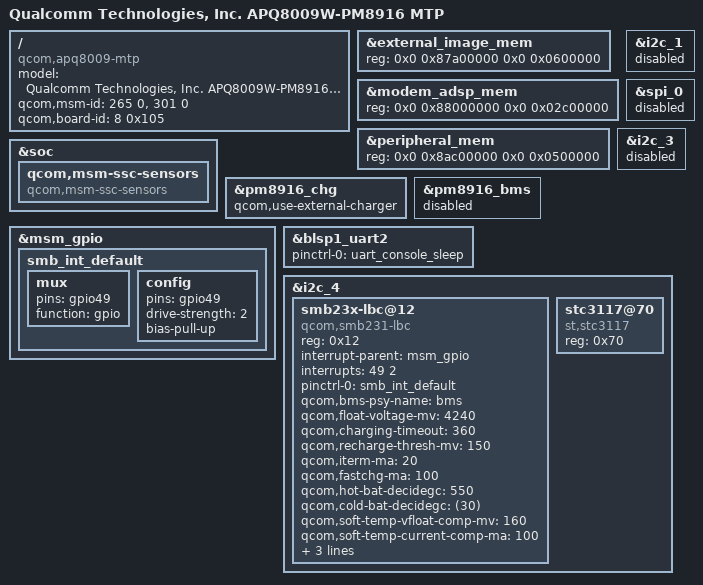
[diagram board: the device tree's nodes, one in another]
/*
 * Copyright (c) 2015-2016, The Linux Foundation. All rights reserved.
 *
 * This program is free software; you can redistribute it and/or modify
 * it under the terms of the GNU General Public License version 2 and
 * only version 2 as published by the Free Software Foundation.
 *
 * This program is distributed in the hope that it will be useful,
 * but WITHOUT ANY WARRANTY; without even the implied warranty of
 * MERCHANTABILITY or FITNESS FOR A PARTICULAR PURPOSE.  See the
 * GNU General Public License for more details.
 */

/dts-v1/;

#include "msm8909-gar-mtp.dtsi"
#include "msm8909w-gar-gpu.dtsi"
#include "msm8909-gar-pm8916.dtsi"
#include "msm8909-gar-pm8916-mtp.dtsi"
#include "msm8909w-gar.dtsi"

/ {
	model = "Qualcomm Technologies, Inc. APQ8009W-PM8916 MTP";
	compatible = "qcom,apq8009-mtp", "qcom,apq8009", "qcom,mtp";
	qcom,msm-id = <265 0>,
		      <301 0>;
	qcom,board-id= <8 0x105>;
};

&external_image_mem {
	reg = <0x0 0x87a00000 0x0 0x0600000>;
};

&modem_adsp_mem {
	reg = <0x0 0x88000000 0x0 0x02c00000>;
};

&peripheral_mem {
	reg = <0x0 0x8ac00000 0x0 0x0500000>;
};

&soc {
	qcom,msm-ssc-sensors {
		compatible = "qcom,msm-ssc-sensors";
	};
};

&i2c_1 {
	status = "disabled";
};

&spi_0 {
	status = "disabled";
};

&i2c_3 {
	status = "disabled";
};

/* Charger/FG configuration */
&pm8916_chg {
	qcom,use-external-charger;
};

&pm8916_bms {
	status = "disabled";
};

&msm_gpio {
	/* Delete gpio58 configuration */
	/delete-node/ tpiu_seta_14;
	/delete-node/ smb_int_pin;
	smb_int_default: smb_int_default {
		mux {
			pins = "gpio49";
			function = "gpio";
		};
		config {
			pins = "gpio49";
			drive-strength = <2>;   /* 2 MA */
			bias-pull-up;           /* PULL UP*/
		};
	};
};

&blsp1_uart2 {
	status = "ok";
	pinctrl-names = "default";
	pinctrl-0 = <&uart_console_sleep>;
};

&i2c_4 {
	status = "ok";
	smb23x-lbc@12 {
		compatible = "qcom,smb231-lbc";
		reg = <0x12>;
		interrupt-parent = <&msm_gpio>;
		interrupts = <49 2>;
		pinctrl-names = "default";
		pinctrl-0 = <&smb_int_default>;

		qcom,bms-psy-name = "bms";
		qcom,float-voltage-mv = <4240>;
		qcom,charging-timeout = <360>;
		qcom,recharge-thresh-mv = <150>;
		qcom,iterm-ma = <20>;
		qcom,fastchg-ma = <100>;
		qcom,hot-bat-decidegc = <550>;
		qcom,cold-bat-decidegc = <(30)>;
		qcom,soft-temp-vfloat-comp-mv = <160>;
		qcom,soft-temp-current-comp-ma = <100>;
		qcom,chg-inhibit-disabled;
		qcom,apsd-disabled;
		qcom,aicl-disabled;
	};

	stc3117@70 {
		compatible = "st,stc3117";
		reg = <0x70>;
	};
};
